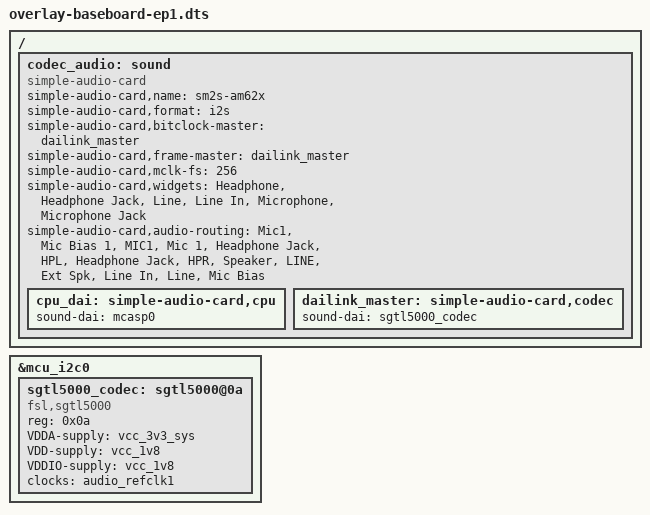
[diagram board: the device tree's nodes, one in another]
/*
 * Copyright (C) 2022 Avnet Embedded GmbH
 *
 * This program is free software; you can redistribute it and/or
 * modify it under the terms of the GNU General Public License as
 * published by the Free Software Foundation version 2.
 *
 * This program is distributed "as is" WITHOUT ANY WARRANTY of any
 * kind, whether express or implied; without even the implied warranty
 * of MERCHANTABILITY or FITNESS FOR A PARTICULAR PURPOSE.  See the
 * GNU General Public License for more details.
 */

/dts-v1/;
/plugin/;


/ {
	fragment@1000 {
		target-path = "/";
		__overlay__ {
			codec_audio: sound {
			        compatible = "simple-audio-card";
			        simple-audio-card,name = "sm2s-am62x";
			        simple-audio-card,format = "i2s";
			        simple-audio-card,bitclock-master = <&dailink_master>;
			        simple-audio-card,frame-master = <&dailink_master>;
				simple-audio-card,mclk-fs = <256>;
			        simple-audio-card,widgets =
			                "Headphone",    "Headphone Jack",
			                "Line", "Line In",
			                "Microphone",   "Microphone Jack";

				simple-audio-card,audio-routing = "Mic1", "Mic Bias 1",
			                                          "MIC1", "Mic 1",
			                                          "Headphone Jack", "HPL",
			                                          "Headphone Jack", "HPR",
			                                          "Speaker", "LINE",
			                                          "Ext Spk", "Line In",
			                                          "Line", "Mic Bias";

			        cpu_dai:simple-audio-card,cpu {
			                sound-dai = <&mcasp0>;
			        };

			        dailink_master: simple-audio-card,codec {
			                sound-dai = <&sgtl5000_codec>;
			        };
			};
		};
	};

	fragment@1002 {
		target = <&mcu_i2c0>;
		__overlay__ {
			#address-cells = <1>;
			#size-cells = <0>;
			sgtl5000_codec: sgtl5000@0a {
			        #sound-dai-cells = <0>;
			        compatible = "fsl,sgtl5000";
			        reg = <0x0a>;

			        VDDA-supply = <&vcc_3v3_sys>;
			        VDD-supply = <&vcc_1v8>;
			        VDDIO-supply = <&vcc_1v8>;
			        clocks = <&audio_refclk1>;
			        clock-names = "mclk";
			};
		};
	};
};
